# ISD91200B_v1 register map
File version: 1.0
ISD91200B_v1 SVD file
Registers are 32-bit, read-write, reset 0x0 unless marked. A register's access mark holds for its fields unless they carry their own. Offsets are from the block's base; lines under a group give offsets from that group; [hi:lo] are bit positions; {n}, {i} and the like mark numbered series; 'fields as' and 'values as' point back to an identical list; <NAME> marks a mode.

## Memory map
0x40004000 WDT size 0x4 — WDT Register Map
0x40008000 RTC size 0x34 — RTC Register Map
0x40010000 TMR0 size 0x10 — TMR Register Map
0x40010020 TMR1 size 0x10 — TMR Register Map
0x40020000 I2C size 0x34 — I2C Register Map
0x40030000 SPI0 blocks up to offset 0x54 — SPI Register Map
0x40038000 SPI1 blocks up to offset 0x3C — SPI1 Register Map
0x40040000 PWM blocks up to offset 0x80 — PWM Register Map
0x40050000 UART0 size 0x34 — UART Register Map
0x40058000 UART1 size 0x34 — UART Register Map
0x40060000 SARADC blocks up to offset 0x70 — SARADC Register Map
0x40070000 DPWM size 0x14 — DPWM Register Map
0x40080000 ANA blocks up to offset 0xA0 — ANA Register Map
0x40084000 BOD blocks up to offset 0x14 — BOD Register Map
0x400A0000 I2S size 0x18 — I2S Register Map
0x400B0000 BIQ blocks up to offset 0x88 — BIQ Register Map
0x400B0090 ALC size 0x10 — ALC Register Map
0x400B00A0 VOLCTRL size 0xC — VOLCTRL Register Map
0x400D0000 CSCAN size 0x1C — CSCAN Register Map
0x400E0000 SDADC size 0x2C — SDADC Register Map
0x50000000 SYS blocks up to offset 0x12C — SYS Register Map
0x50000200 CLK size 0x30 — CLK Register Map
0x50000300 INT size 0x88 — INT Register Map
0x50004000 GPIO blocks up to offset 0x184 — GPIO Register Map
0x50008000 PDMA0 blocks up to offset 0x3C — PDMA Register Map
0x50008100 PDMA1 blocks up to offset 0x3C — PDMA Register Map
0x50008200 PDMA2 blocks up to offset 0x3C — PDMA Register Map
0x50008300 PDMA3 blocks up to offset 0x3C — PDMA Register Map
0x50008F00 PDMA_GCR size 0x10 — PDMA Register Map
0x5000C000 FMC size 0x18 — FMC Register Map
0xE000E000 SYSTICK blocks up to offset 0x1C — SYSTICK Register Map
0xE000E100 SCS blocks up to offset 0x320 — SCS Register Map
0xE000ED00 SYSINFO blocks up to offset 0x24 — SYSINFO Register Map

## SYSTICK — SYSTICK Register Map
Base 0xE000E000
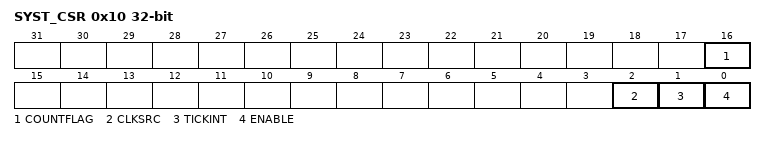
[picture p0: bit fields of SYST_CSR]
0x10 SYST_CSR — SysTick Control and Status Register
  [16] COUNTFLAG — Count Flag. Returns 1 if timer counted to 0 since last time this register was read.
    0=Cleared on read or by a write to the Current Value register; 1=Set by a count transition from 1 to 0
  [2] CLKSRC — Clock Source
    0=Core clock unused; 1=Core clock used for SysTick, this bit will read as 1 and ignore writes
  [1] TICKINT — Enables SysTick Exception Request
    0=Counting down to 0 does not cause the SysTick exception to be pended. Software can use COUNTFLAG to determine if a count to zero has occurred; 1=Counting down to 0 will cause SysTick exception to be pended. Clearing the SysTick Current Value register by a register write in software will not cause SysTick to be pended
  [0] ENABLE
    0=The counter is disabled; 1=The counter will operate in a multi-shot manner
0x14 SYST_RVR reset not defined — SysTick Reload Value Register
  [23:0] RELOAD — SysTick Reload. Value to load into the Current Value register when the counter reaches 0. To generate a multi-shot timer with a period of N processor clock cycles, use a RELOAD value of N-1. For example, if the SysTick interrupt is required every 200 clock pulses, set RELOAD to 199.
0x18 SYST_CVR reset not defined — SysTick Current Value Register
  [23:0] CURRENT — Current Counter Value. This is the value of the counter at the time it is sampled. The counter does not provide read-modify-write protection. The register is write-clear. A software write of any value will clear the register to 0 and also clear the COUNTFLAG bit.

## SCS — SCS Register Map
Base 0xE000E100
0x00 NVIC_ISER — IRQ0 ~ IRQ31 Set-enable Control Register
  [31:0] SETENA — Set-enable Control. Enable one or more interrupts within a group of 32. Each bit represents an interrupt number from IRQ0 ~ IRQ31 (Vector number from 16 ~ 47). Writing 1 will enable the associated interrupt. Writing 0 has no effect. The register reads back the current enable state.
0x80 NVIC_ICER — IRQ0 ~ IRQ31 Clear-enable Control Register
  [31:0] CLRENA — Clear-enable Control. Disable one or more interrupts within a group of 32. Each bit represents an interrupt number from IRQ0 ~ IRQ31 (Vector number from 16 ~ 47). Writing 1 will disable the associated interrupt. Writing 0 has no effect. The register reads back with the current enable state.
0x100 NVIC_ISPR — IRQ0 ~ IRQ31 Set-pending Control Register
  [31:0] SETPEND — Set-pending Control. Writing 1 to a bit forces pending state of the associated interrupt under software control. Each bit represents an interrupt number from IRQ0 ~ IRQ31 (Vector number from 16 ~ 47). Writing 0 has no effect. The register reads back with the current pending state.
0x180 NVIC_ICPR — IRQ0 ~ IRQ31 Clear-pending Control Register
  [31:0] CLRPEND — Clear-pending Control. Writing 1 to a bit to clear the pending state of associated interrupt under software control. Each bit represents an interrupt number from IRQ0 ~ IRQ31 (Vector number from 16 ~ 47). Writing 0 has no effect. The register reads back with the current pending state.
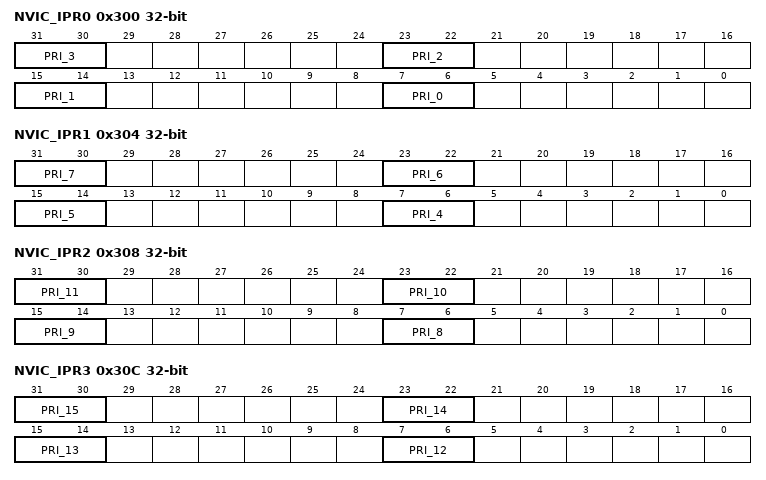
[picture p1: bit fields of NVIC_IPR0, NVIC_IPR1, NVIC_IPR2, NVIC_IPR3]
0x300 NVIC_IPR0 — IRQ0 ~ IRQ3 Priority Control Register
  [8n+7:8n+6] PRI_{n} (n=0..3) — Priority of IRQ{n} "0" denotes the highest priority and "3" denotes lowest priority
0x304 NVIC_IPR1 — IRQ4 ~ IRQ7 Priority Control Register
  [8n-25:8n-26] PRI_{n} (n=4..7) — Priority of IRQ{n} "0" denotes the highest priority and "3" denotes lowest priority
0x308 NVIC_IPR2 — IRQ8 ~ IRQ11 Priority Control Register
  [8n-57:8n-58] PRI_{n} (n=8..11) — Priority of IRQ{n} "0" denotes the highest priority and "3" denotes lowest priority
0x30C NVIC_IPR3 — IRQ12 ~ IRQ15 Priority Control Register
  [8n-89:8n-90] PRI_{n} (n=12..15) — Priority of IRQ{n} "0" denotes the highest priority and "3" denotes lowest priority
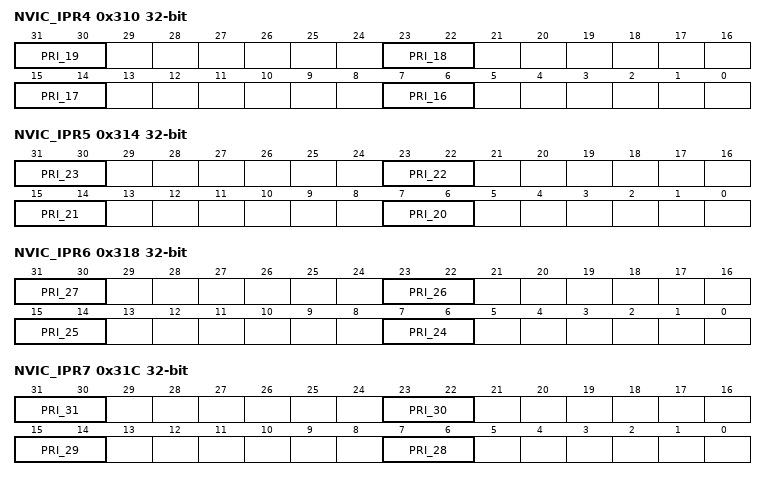
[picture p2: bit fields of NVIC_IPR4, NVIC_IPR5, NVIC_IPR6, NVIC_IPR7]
0x310 NVIC_IPR4 — IRQ16 ~ IRQ19 Priority Control Register
  [8n-121:8n-122] PRI_{n} (n=16..19) — Priority of IRQ{n} "0" denotes the highest priority and "3" denotes lowest priority
0x314 NVIC_IPR5 — IRQ20 ~ IRQ23 Priority Control Register
  [8n-153:8n-154] PRI_{n} (n=20..23) — Priority of IRQ{n} "0" denotes the highest priority and "3" denotes lowest priority
0x318 NVIC_IPR6 — IRQ24 ~ IRQ27 Priority Control Register
  [8n-185:8n-186] PRI_{n} (n=24..27) — Priority of IRQ{n} "0" denotes the highest priority and "3" denotes lowest priority
0x31C NVIC_IPR7 — IRQ28 ~ IRQ31 Priority Control Register
  [8n-217:8n-218] PRI_{n} (n=28..31) — Priority of IRQ{n} "0" denotes the highest priority and "3" denotes lowest priority
